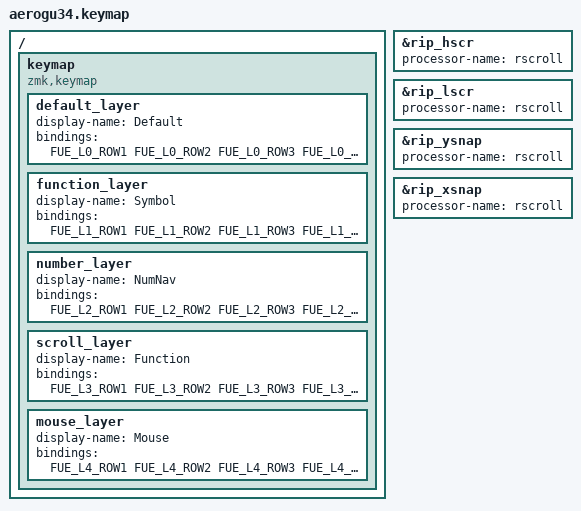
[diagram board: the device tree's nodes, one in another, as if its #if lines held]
/*
 * aerogu34 キーマップ(ラッパー)
 *
 * ★実際のキー割り当ては共通リポジトリで定義★
 *   https://github.com/lionexile-cpu/zmk-keymap-common
 *   include/fue/keymap34.dtsi
 * キーマップ変更は上記ファイルを編集すること。
 *
 * このファイルは共通34キー定義を自機のマトリクスへ展開するだけ。
 */

#define ZMK_POINTING_DEFAULT_SCRL_VAL 200

#include <dt-bindings/zmk/mouse.h>

/* ランタイムマクロ挙動 (&rmacro) の定義。DYA StudioのMacro & Comboタブから
 * キーへ割り当てる際に使用 (zmk-feature-runtime-macro 2026-11-27追加・jisaku_1と統一) */
#include <behaviors/runtime_macro.dtsi>

#include <fue/keymap34.dtsi>

/* runtime-input-processor の既定ビヘイビア(1.5x/0.5x Speed Scroll・X/Y Axis Snap)は
 * processor-name = "scroll" を探すが、このキーボードのスクロール用プロセッサは
 * "rscroll" なので見つからず初期化に失敗していた。失敗したビヘイビアは local id が
 * 0 のまま残り、DYA Studio がビヘイビア詳細を取得した瞬間にファームが落ちて
 * 全キーが「—」表示になっていた (2026-11-27)。名前を合わせる。 */
#if __has_include(<behaviors/runtime-input-processor.dtsi>)
&rip_hscr { processor-name = "rscroll"; };
&rip_lscr { processor-name = "rscroll"; };
&rip_ysnap { processor-name = "rscroll"; };
&rip_xsnap { processor-name = "rscroll"; };
#endif

/ {
    keymap {
        compatible = "zmk,keymap";

        default_layer {
            display-name = "Default";
            bindings = <
FUE_L0_ROW1
FUE_L0_ROW2
FUE_L0_ROW3
FUE_L0_THUMBS
            >;
        };

        function_layer {
            display-name = "Symbol";
            bindings = <
FUE_L1_ROW1
FUE_L1_ROW2
FUE_L1_ROW3
FUE_L1_THUMBS
            >;
        };

        number_layer {
            display-name = "NumNav";
            bindings = <
FUE_L2_ROW1
FUE_L2_ROW2
FUE_L2_ROW3
FUE_L2_THUMBS
            >;
        };

        scroll_layer {
            display-name = "Function";
            bindings = <
FUE_L3_ROW1
FUE_L3_ROW2
FUE_L3_ROW3
FUE_L3_THUMBS
            >;
        };

        mouse_layer {
            display-name = "Mouse";
            bindings = <
FUE_L4_ROW1
FUE_L4_ROW2
FUE_L4_ROW3
FUE_L4_THUMBS
            >;
        };
    };
};
